VERSION ""

NS_ :

BS_:

BU_: K109_FCM B233B_LRR NEO K124_ASCM
VAL_TABLE_ RangeMode 1 "Active" 0 "Inactive" ;
VAL_TABLE_ TrkConf 3 "Confident" 2 "Speculative" 1 "Highly speculative" 0 "Invalid" ;
VAL_TABLE_ TrkMeasStatus 3 "Measured current cycle" 2 "Latent track not detected " 1 "New object" 0 "No object" ;
VAL_TABLE_ TrkDynProp 4 "Moving in opposite direction" 3 "Moving in same direction " 2 "Has moved but currenty stopped" 1 "Has never moved," 0 "Unkown" ;

BO_ 3221225472 VECTOR__INDEPENDENT_SIG_MSG: 0 Vector__XXX
 SG_ Always12 : 0|8@0+ (1,0) [0|0] "" Vector__XXX
 SG_ TimeStatusChecksum : 0|12@0+ (1,0) [0|0] "" Vector__XXX

BO_ 161 ASCMTimeStatus: 7 NEO
 SG_ TimeStatus : 7|28@0+ (1,0) [0|0] ""  B233B_LRR
 SG_ RollingCounter : 27|2@0+ (1,0) [0|0] ""  B233B_LRR

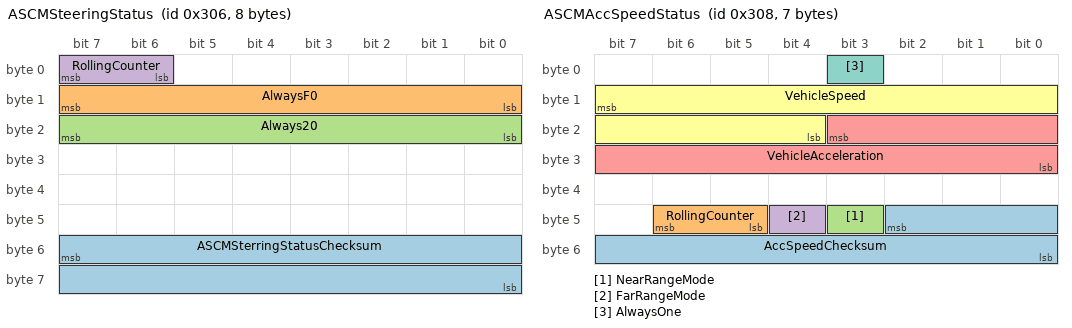
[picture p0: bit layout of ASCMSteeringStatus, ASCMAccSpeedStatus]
BO_ 774 ASCMSteeringStatus: 8 NEO
 SG_ ASCMSterringStatusChecksum : 55|16@0+ (1,0) [0|0] ""  B233B_LRR
 SG_ AlwaysF0 : 15|8@0+ (1,0) [0|0] ""  B233B_LRR
 SG_ Always20 : 23|8@0+ (1,0) [0|0] ""  B233B_LRR
 SG_ RollingCounter : 7|2@0+ (1,0) [0|0] ""  B233B_LRR

BO_ 784 ASCMHeadlight: 2 NEO
 SG_ Always42 : 7|8@0+ (1,0) [0|0] ""  B233B_LRR
 SG_ Always4 : 15|8@0+ (1,0) [0|0] ""  B233B_LRR

BO_ 776 ASCMAccSpeedStatus: 7 NEO
 SG_ AccSpeedChecksum : 42|11@0+ (1,0) [0|0] ""  B233B_LRR
 SG_ RollingCounter : 46|2@0+ (1,0) [0|0] ""  B233B_LRR
 SG_ NearRangeMode : 43|1@0+ (1,0) [0|0] ""  B233B_LRR
 SG_ FarRangeMode : 44|1@0+ (1,0) [0|0] ""  B233B_LRR
 SG_ VehicleAcceleration : 19|12@0+ (1,0) [0|0] ""  B233B_LRR
 SG_ VehicleSpeed : 15|12@0+ (1,0) [0|0] ""  B233B_LRR
 SG_ AlwaysOne : 3|1@0+ (1,0) [0|0] ""  B233B_LRR

BO_ 1120 F_LRR_Obj_Header: 8 LRR_FO
 SG_ FLRRRollingCount : 7|2@0+ (1,0) [0|3] ""  EOCM_F_FO
 SG_ FLRRModeCmdFdbk : 23|3@0+ (1,0) [0|7] ""  EOCM_F_FO
 SG_ FLRRNumValidTargets : 20|5@0+ (1,0) [0|31] ""  EOCM_F_FO
 SG_ FLRRTimeStampV : 31|1@0+ (1,0) [0|1] ""  EOCM_F_FO
 SG_ FLRRTimeStamp : 2|11@0+ (1,0) [0|2047] "ms"  EOCM_F_FO
 SG_ FLRRRoadTypeInfo : 5|3@0+ (1,0) [0|7] ""  EOCM_F_FO
 SG_ FLRRBurstChecksum : 55|16@0+ (1,0) [0|65535] ""  EOCM_F_FO
 SG_ FLRRDiagSpare : 30|1@0+ (1,0) [0|1] ""  EOCM_F_FO
 SG_ FLRRVltgOutRngLo : 44|1@0+ (1,0) [0|1] ""  EOCM_F_FO
 SG_ FLRRVltgOutRngHi : 43|1@0+ (1,0) [0|1] ""  EOCM_F_FO
 SG_ FLRRSvcAlgnInPrcs : 38|1@0+ (1,0) [0|1] ""  EOCM_F_FO
 SG_ FLRRSnsrBlckd : 45|1@0+ (1,0) [0|1] ""  EOCM_F_FO
 SG_ FLRRSnstvFltPrsntInt : 24|1@0+ (1,0) [0|1] ""  EOCM_F_FO
 SG_ FLRRPlntAlgnInProc : 37|1@0+ (1,0) [0|1] ""  EOCM_F_FO
 SG_ FLRRMsalgnYawRt : 47|1@0+ (1,0) [0|1] ""  EOCM_F_FO
 SG_ FLRRMsalgnYawLt : 46|1@0+ (1,0) [0|1] ""  EOCM_F_FO
 SG_ FLRRLonVelPlsblityFlt : 35|1@0+ (1,0) [0|1] ""  EOCM_F_FO
 SG_ FLRRYawRtPlsblityFlt : 34|1@0+ (1,0) [0|1] ""  EOCM_F_FO
 SG_ FLRRMsalgnPtchUp : 32|1@0+ (1,0) [0|1] ""  EOCM_F_FO
 SG_ FLRRMsalgnPtchDn : 33|1@0+ (1,0) [0|1] ""  EOCM_F_FO
 SG_ FLRRInitDiagCmplt : 40|1@0+ (1,0) [0|1] ""  EOCM_F_FO
 SG_ FLRRHWFltPrsntInt : 25|1@0+ (1,0) [0|1] ""  EOCM_F_FO
 SG_ FLRRExtIntrfrnc : 36|1@0+ (1,0) [0|1] ""  EOCM_F_FO
 SG_ FLRRCANSgnlSpvFld : 29|1@0+ (1,0) [0|1] ""  EOCM_F_FO
 SG_ FLRRCANRxErr : 28|1@0+ (1,0) [0|1] ""  EOCM_F_FO
 SG_ FLRRTunlDtctd : 27|1@0+ (1,0) [0|1] ""  EOCM_F_FO
 SG_ FLRRAmbTmpOutRngLw : 42|1@0+ (1,0) [0|1] ""  EOCM_F_FO
 SG_ FLRRAmbTmpOutRngHi : 41|1@0+ (1,0) [0|1] ""  EOCM_F_FO
 SG_ FLRRAntTngFltPrsnt : 26|1@0+ (1,0) [0|1] ""  EOCM_F_FO
 SG_ FLRRAlgnFltPrsnt : 39|1@0+ (1,0) [0|1] ""  EOCM_F_FO

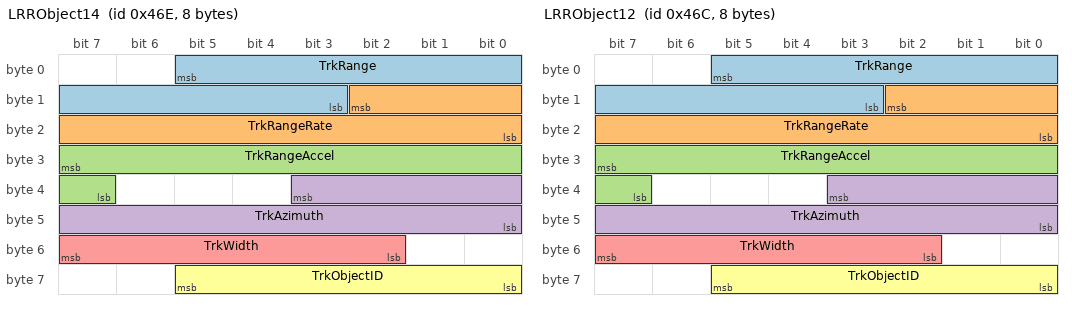
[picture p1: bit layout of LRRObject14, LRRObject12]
BO_ 1134 LRRObject14: 8 B233B_LRR
 SG_ TrkRange : 5|11@0+ (0.125,0) [0|255.875] "m"  NEO
 SG_ TrkRangeRate : 10|11@0- (0.125,0) [-128|127.875] "m/s"  NEO
 SG_ TrkRangeAccel : 31|9@0- (0.125,0) [-32|31.875] "m/s^2"  NEO
 SG_ TrkAzimuth : 35|12@0- (0.125,0) [-256|255.875] "deg"  NEO
 SG_ TrkWidth : 55|6@0+ (0.25,0) [0|15.75] "m"  NEO
 SG_ TrkObjectID : 61|6@0+ (1,0) [0|63] ""  NEO

BO_ 1132 LRRObject12: 8 B233B_LRR
 SG_ TrkRange : 5|11@0+ (0.125,0) [0|255.875] "m"  NEO
 SG_ TrkRangeRate : 10|11@0- (0.125,0) [-128|127.875] "m/s"  NEO
 SG_ TrkRangeAccel : 31|9@0- (0.125,0) [-32|31.875] "m/s^2"  NEO
 SG_ TrkAzimuth : 35|12@0- (0.125,0) [-256|255.875] "deg"  NEO
 SG_ TrkWidth : 55|6@0+ (0.25,0) [0|15.75] "m"  NEO
 SG_ TrkObjectID : 61|6@0+ (1,0) [0|63] ""  NEO

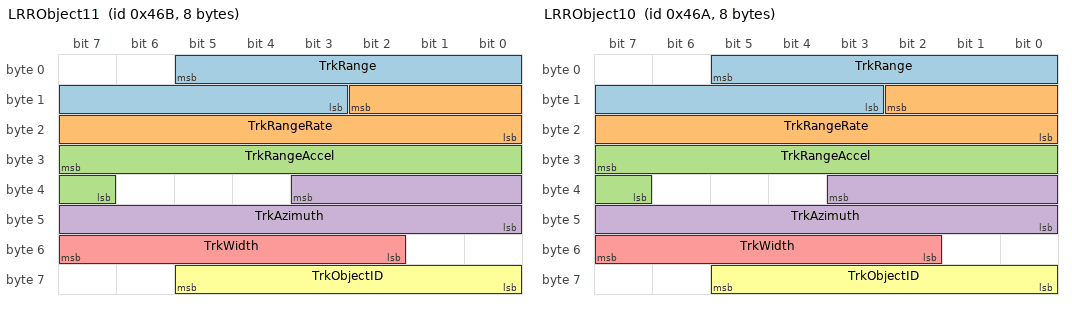
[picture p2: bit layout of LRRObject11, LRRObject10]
BO_ 1131 LRRObject11: 8 B233B_LRR
 SG_ TrkRange : 5|11@0+ (0.125,0) [0|255.875] "m"  NEO
 SG_ TrkRangeRate : 10|11@0- (0.125,0) [-128|127.875] "m/s"  NEO
 SG_ TrkRangeAccel : 31|9@0- (0.125,0) [-32|31.875] "m/s^2"  NEO
 SG_ TrkAzimuth : 35|12@0- (0.125,0) [-256|255.875] "deg"  NEO
 SG_ TrkWidth : 55|6@0+ (0.25,0) [0|15.75] "m"  NEO
 SG_ TrkObjectID : 61|6@0+ (1,0) [0|63] ""  NEO

BO_ 1130 LRRObject10: 8 B233B_LRR
 SG_ TrkRange : 5|11@0+ (0.125,0) [0|255.875] "m"  NEO
 SG_ TrkRangeRate : 10|11@0- (0.125,0) [-128|127.875] "m/s"  NEO
 SG_ TrkRangeAccel : 31|9@0- (0.125,0) [-32|31.875] "m/s^2"  NEO
 SG_ TrkAzimuth : 35|12@0- (0.125,0) [-256|255.875] "deg"  NEO
 SG_ TrkWidth : 55|6@0+ (0.25,0) [0|15.75] "m"  NEO
 SG_ TrkObjectID : 61|6@0+ (1,0) [0|63] ""  NEO

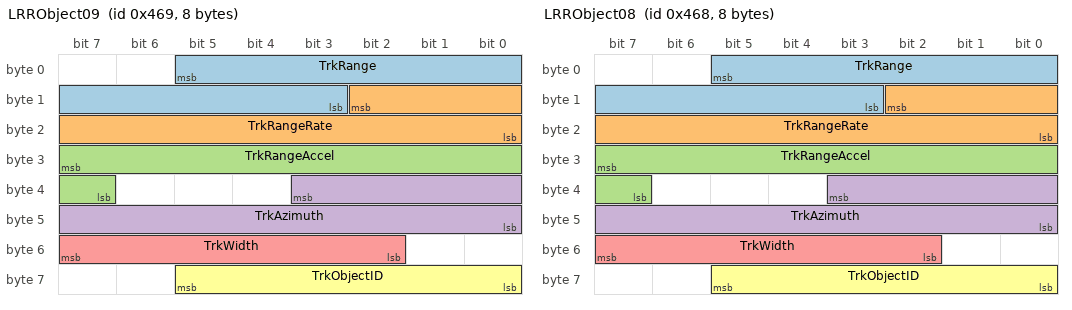
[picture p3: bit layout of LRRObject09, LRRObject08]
BO_ 1129 LRRObject09: 8 B233B_LRR
 SG_ TrkRange : 5|11@0+ (0.125,0) [0|255.875] "m"  NEO
 SG_ TrkRangeRate : 10|11@0- (0.125,0) [-128|127.875] "m/s"  NEO
 SG_ TrkRangeAccel : 31|9@0- (0.125,0) [-32|31.875] "m/s^2"  NEO
 SG_ TrkAzimuth : 35|12@0- (0.125,0) [-256|255.875] "deg"  NEO
 SG_ TrkWidth : 55|6@0+ (0.25,0) [0|15.75] "m"  NEO
 SG_ TrkObjectID : 61|6@0+ (1,0) [0|63] ""  NEO

BO_ 1128 LRRObject08: 8 B233B_LRR
 SG_ TrkRange : 5|11@0+ (0.125,0) [0|255.875] "m"  NEO
 SG_ TrkRangeRate : 10|11@0- (0.125,0) [-128|127.875] "m/s"  NEO
 SG_ TrkRangeAccel : 31|9@0- (0.125,0) [-32|31.875] "m/s^2"  NEO
 SG_ TrkAzimuth : 35|12@0- (0.125,0) [-256|255.875] "deg"  NEO
 SG_ TrkWidth : 55|6@0+ (0.25,0) [0|15.75] "m"  NEO
 SG_ TrkObjectID : 61|6@0+ (1,0) [0|63] ""  NEO

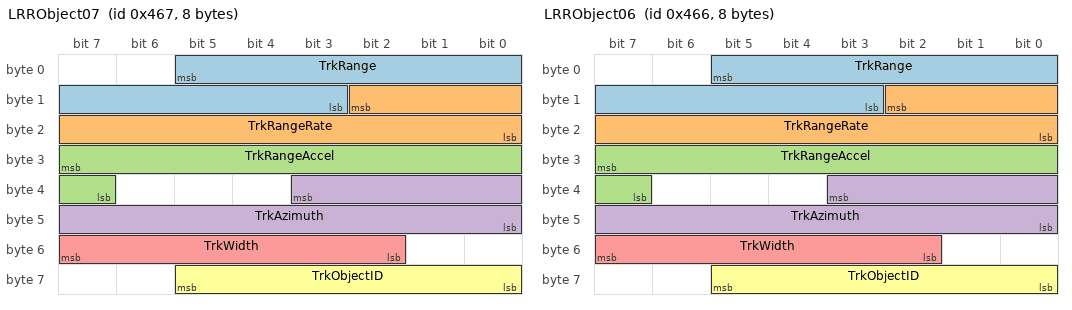
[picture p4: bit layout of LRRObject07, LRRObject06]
BO_ 1127 LRRObject07: 8 B233B_LRR
 SG_ TrkRange : 5|11@0+ (0.125,0) [0|255.875] "m"  NEO
 SG_ TrkRangeRate : 10|11@0- (0.125,0) [-128|127.875] "m/s"  NEO
 SG_ TrkRangeAccel : 31|9@0- (0.125,0) [-32|31.875] "m/s^2"  NEO
 SG_ TrkAzimuth : 35|12@0- (0.125,0) [-256|255.875] "deg"  NEO
 SG_ TrkWidth : 55|6@0+ (0.25,0) [0|15.75] "m"  NEO
 SG_ TrkObjectID : 61|6@0+ (1,0) [0|63] ""  NEO

BO_ 1126 LRRObject06: 8 B233B_LRR
 SG_ TrkRange : 5|11@0+ (0.125,0) [0|255.875] "m"  NEO
 SG_ TrkRangeRate : 10|11@0- (0.125,0) [-128|127.875] "m/s"  NEO
 SG_ TrkRangeAccel : 31|9@0- (0.125,0) [-32|31.875] "m/s^2"  NEO
 SG_ TrkAzimuth : 35|12@0- (0.125,0) [-256|255.875] "deg"  NEO
 SG_ TrkWidth : 55|6@0+ (0.25,0) [0|15.75] "m"  NEO
 SG_ TrkObjectID : 61|6@0+ (1,0) [0|63] ""  NEO

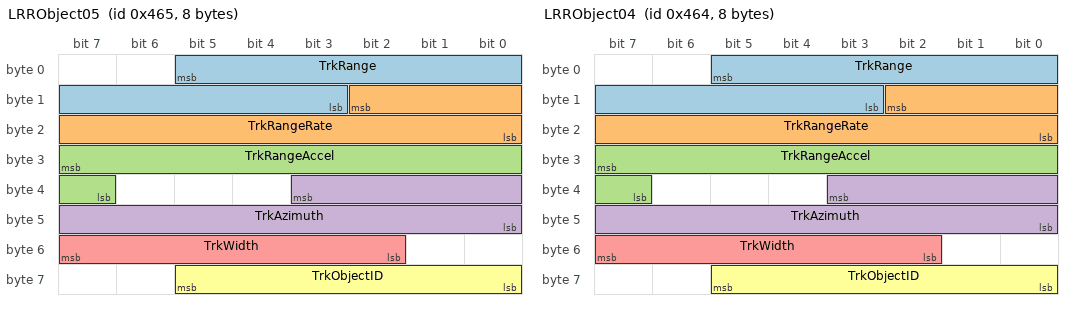
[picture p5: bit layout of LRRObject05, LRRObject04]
BO_ 1125 LRRObject05: 8 B233B_LRR
 SG_ TrkRange : 5|11@0+ (0.125,0) [0|255.875] "m"  NEO
 SG_ TrkRangeRate : 10|11@0- (0.125,0) [-128|127.875] "m/s"  NEO
 SG_ TrkRangeAccel : 31|9@0- (0.125,0) [-32|31.875] "m/s^2"  NEO
 SG_ TrkAzimuth : 35|12@0- (0.125,0) [-256|255.875] "deg"  NEO
 SG_ TrkWidth : 55|6@0+ (0.25,0) [0|15.75] "m"  NEO
 SG_ TrkObjectID : 61|6@0+ (1,0) [0|63] ""  NEO

BO_ 1124 LRRObject04: 8 B233B_LRR
 SG_ TrkRange : 5|11@0+ (0.125,0) [0|255.875] "m"  NEO
 SG_ TrkRangeRate : 10|11@0- (0.125,0) [-128|127.875] "m/s"  NEO
 SG_ TrkRangeAccel : 31|9@0- (0.125,0) [-32|31.875] "m/s^2"  NEO
 SG_ TrkAzimuth : 35|12@0- (0.125,0) [-256|255.875] "deg"  NEO
 SG_ TrkWidth : 55|6@0+ (0.25,0) [0|15.75] "m"  NEO
 SG_ TrkObjectID : 61|6@0+ (1,0) [0|63] ""  NEO

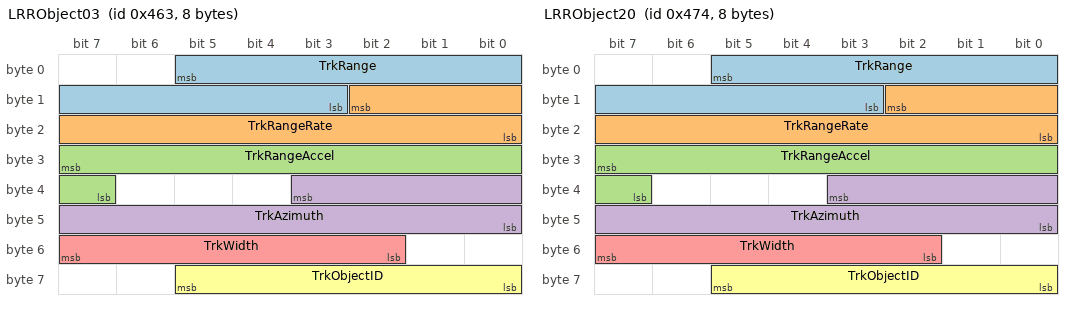
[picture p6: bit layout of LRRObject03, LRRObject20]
BO_ 1123 LRRObject03: 8 B233B_LRR
 SG_ TrkRange : 5|11@0+ (0.125,0) [0|255.875] "m"  NEO
 SG_ TrkRangeRate : 10|11@0- (0.125,0) [-128|127.875] "m/s"  NEO
 SG_ TrkRangeAccel : 31|9@0- (0.125,0) [-32|31.875] "m/s^2"  NEO
 SG_ TrkAzimuth : 35|12@0- (0.125,0) [-256|255.875] "deg"  NEO
 SG_ TrkWidth : 55|6@0+ (0.25,0) [0|15.75] "m"  NEO
 SG_ TrkObjectID : 61|6@0+ (1,0) [0|63] ""  NEO

BO_ 1140 LRRObject20: 8 B233B_LRR
 SG_ TrkRange : 5|11@0+ (0.125,0) [0|255.875] "m"  NEO
 SG_ TrkRangeRate : 10|11@0- (0.125,0) [-128|127.875] "m/s"  NEO
 SG_ TrkRangeAccel : 31|9@0- (0.125,0) [-32|31.875] "m/s^2"  NEO
 SG_ TrkAzimuth : 35|12@0- (0.125,0) [-256|255.875] "deg"  NEO
 SG_ TrkWidth : 55|6@0+ (0.25,0) [0|15.75] "m"  NEO
 SG_ TrkObjectID : 61|6@0+ (1,0) [0|63] ""  NEO

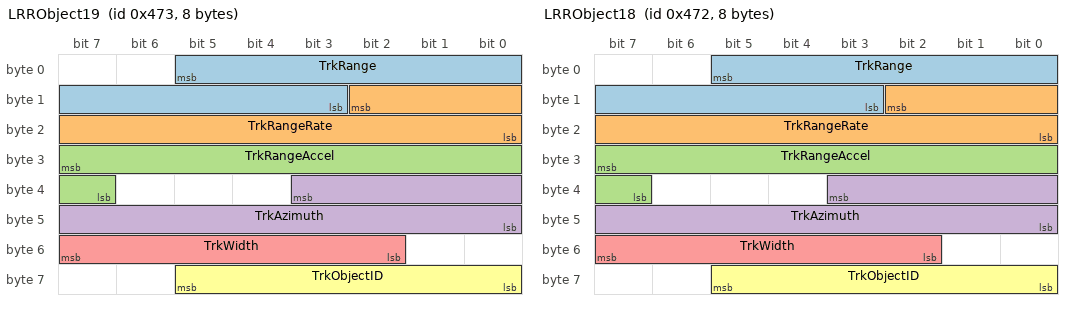
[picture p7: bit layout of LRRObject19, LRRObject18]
BO_ 1139 LRRObject19: 8 B233B_LRR
 SG_ TrkRange : 5|11@0+ (0.125,0) [0|255.875] "m"  NEO
 SG_ TrkRangeRate : 10|11@0- (0.125,0) [-128|127.875] "m/s"  NEO
 SG_ TrkRangeAccel : 31|9@0- (0.125,0) [-32|31.875] "m/s^2"  NEO
 SG_ TrkAzimuth : 35|12@0- (0.125,0) [-256|255.875] "deg"  NEO
 SG_ TrkWidth : 55|6@0+ (0.25,0) [0|15.75] "m"  NEO
 SG_ TrkObjectID : 61|6@0+ (1,0) [0|63] ""  NEO

BO_ 1138 LRRObject18: 8 B233B_LRR
 SG_ TrkRange : 5|11@0+ (0.125,0) [0|255.875] "m"  NEO
 SG_ TrkRangeRate : 10|11@0- (0.125,0) [-128|127.875] "m/s"  NEO
 SG_ TrkRangeAccel : 31|9@0- (0.125,0) [-32|31.875] "m/s^2"  NEO
 SG_ TrkAzimuth : 35|12@0- (0.125,0) [-256|255.875] "deg"  NEO
 SG_ TrkWidth : 55|6@0+ (0.25,0) [0|15.75] "m"  NEO
 SG_ TrkObjectID : 61|6@0+ (1,0) [0|63] ""  NEO

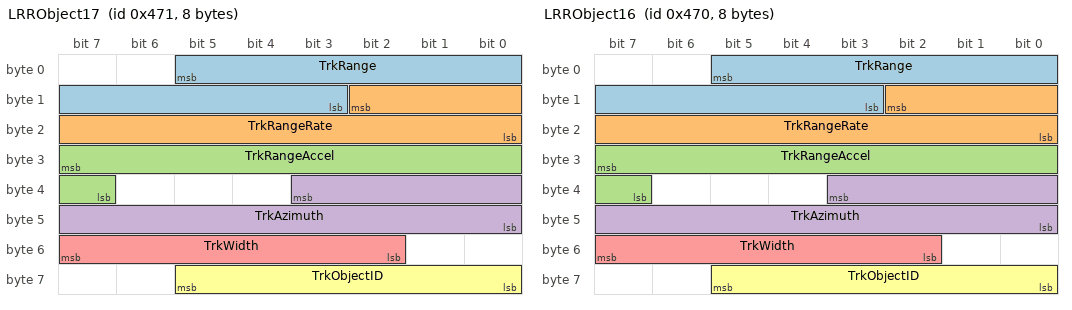
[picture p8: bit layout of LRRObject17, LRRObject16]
BO_ 1137 LRRObject17: 8 B233B_LRR
 SG_ TrkRange : 5|11@0+ (0.125,0) [0|255.875] "m"  NEO
 SG_ TrkRangeRate : 10|11@0- (0.125,0) [-128|127.875] "m/s"  NEO
 SG_ TrkRangeAccel : 31|9@0- (0.125,0) [-32|31.875] "m/s^2"  NEO
 SG_ TrkAzimuth : 35|12@0- (0.125,0) [-256|255.875] "deg"  NEO
 SG_ TrkWidth : 55|6@0+ (0.25,0) [0|15.75] "m"  NEO
 SG_ TrkObjectID : 61|6@0+ (1,0) [0|63] ""  NEO

BO_ 1136 LRRObject16: 8 B233B_LRR
 SG_ TrkRange : 5|11@0+ (0.125,0) [0|255.875] "m"  NEO
 SG_ TrkRangeRate : 10|11@0- (0.125,0) [-128|127.875] "m/s"  NEO
 SG_ TrkRangeAccel : 31|9@0- (0.125,0) [-32|31.875] "m/s^2"  NEO
 SG_ TrkAzimuth : 35|12@0- (0.125,0) [-256|255.875] "deg"  NEO
 SG_ TrkWidth : 55|6@0+ (0.25,0) [0|15.75] "m"  NEO
 SG_ TrkObjectID : 61|6@0+ (1,0) [0|63] ""  NEO

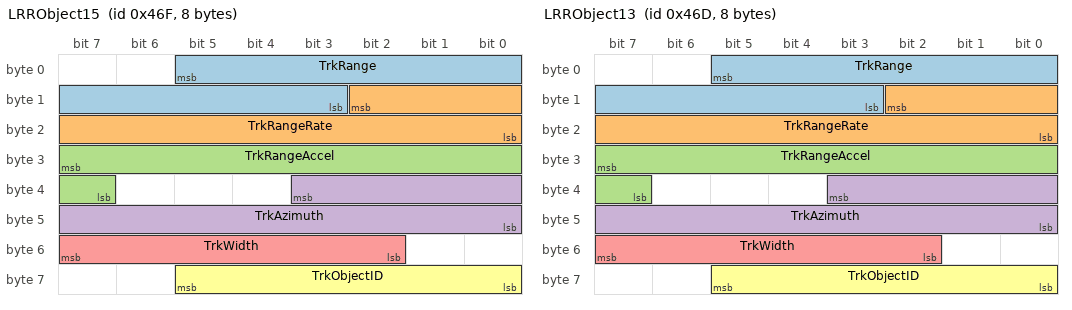
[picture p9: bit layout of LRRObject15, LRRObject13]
BO_ 1135 LRRObject15: 8 B233B_LRR
 SG_ TrkRange : 5|11@0+ (0.125,0) [0|255.875] "m"  NEO
 SG_ TrkRangeRate : 10|11@0- (0.125,0) [-128|127.875] "m/s"  NEO
 SG_ TrkRangeAccel : 31|9@0- (0.125,0) [-32|31.875] "m/s^2"  NEO
 SG_ TrkAzimuth : 35|12@0- (0.125,0) [-256|255.875] "deg"  NEO
 SG_ TrkWidth : 55|6@0+ (0.25,0) [0|15.75] "m"  NEO
 SG_ TrkObjectID : 61|6@0+ (1,0) [0|63] ""  NEO

BO_ 1133 LRRObject13: 8 B233B_LRR
 SG_ TrkRange : 5|11@0+ (0.125,0) [0|255.875] "m"  NEO
 SG_ TrkRangeRate : 10|11@0- (0.125,0) [-128|127.875] "m/s"  NEO
 SG_ TrkRangeAccel : 31|9@0- (0.125,0) [-32|31.875] "m/s^2"  NEO
 SG_ TrkAzimuth : 35|12@0- (0.125,0) [-256|255.875] "deg"  NEO
 SG_ TrkWidth : 55|6@0+ (0.25,0) [0|15.75] "m"  NEO
 SG_ TrkObjectID : 61|6@0+ (1,0) [0|63] ""  NEO

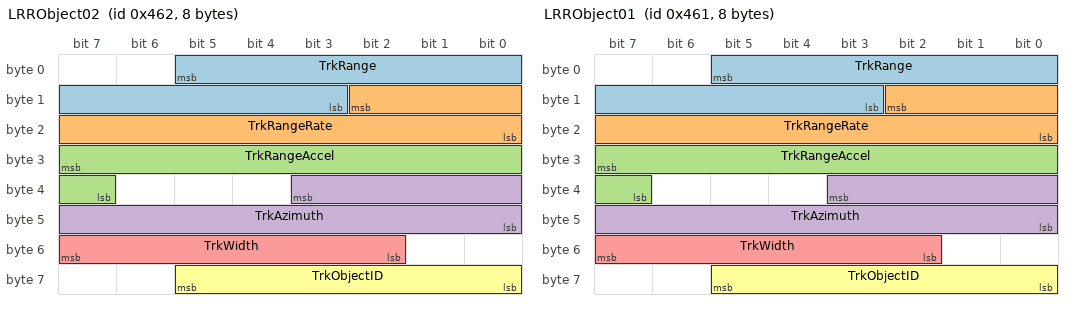
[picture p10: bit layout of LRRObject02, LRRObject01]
BO_ 1122 LRRObject02: 8 B233B_LRR
 SG_ TrkRange : 5|11@0+ (0.125,0) [0|255.875] "m"  NEO
 SG_ TrkRangeRate : 10|11@0- (0.125,0) [-128|127.875] "m/s"  NEO
 SG_ TrkRangeAccel : 31|9@0- (0.125,0) [-32|31.875] "m/s^2"  NEO
 SG_ TrkAzimuth : 35|12@0- (0.125,0) [-256|255.875] "deg"  NEO
 SG_ TrkWidth : 55|6@0+ (0.25,0) [0|15.75] "m"  NEO
 SG_ TrkObjectID : 61|6@0+ (1,0) [0|63] ""  NEO

BO_ 1121 LRRObject01: 8 B233B_LRR
 SG_ TrkRange : 5|11@0+ (0.125,0) [0|255.875] "m"  NEO
 SG_ TrkRangeRate : 10|11@0- (0.125,0) [-128|127.875] "m/s"  NEO
 SG_ TrkRangeAccel : 31|9@0- (0.125,0) [-32|31.875] "m/s^2"  NEO
 SG_ TrkAzimuth : 35|12@0- (0.125,0) [-256|255.875] "deg"  NEO
 SG_ TrkWidth : 55|6@0+ (0.25,0) [0|15.75] "m"  NEO
 SG_ TrkObjectID : 61|6@0+ (1,0) [0|63] ""  NEO

BO_TX_BU_ 161 : K124_ASCM,NEO;
BO_TX_BU_ 774 : K124_ASCM,NEO;
BO_TX_BU_ 784 : K124_ASCM,NEO;
BO_TX_BU_ 776 : K124_ASCM,NEO;

CM_ BU_ K109_FCM "Frontview Camera Module ";
CM_ BU_ B233B_LRR "Radar Sensor Module Long Range";
CM_ BU_ NEO "Comma NEO";
CM_ BU_ K124_ASCM "Active Safety Control Module";
CM_ BO_ 3221225472 "This is a message for not used signals, created by Vector CANdb++ DBC OLE DB Provider.";
BA_DEF_  "UseGMParameterIDs" INT 0 0;
BA_DEF_  "ProtocolType" STRING ;
BA_DEF_  "BusType" STRING ;
BA_DEF_DEF_  "UseGMParameterIDs" 1;
BA_DEF_DEF_  "ProtocolType" "GMLAN";
BA_DEF_DEF_  "BusType" "";
BA_ "BusType" "CAN";
BA_ "UseGMParameterIDs" 0;
VAL_ 776 NearRangeMode 1 "Active" 0 "Inactive" ;
VAL_ 776 FarRangeMode 1 "Active" 0 "Inactive" ;
